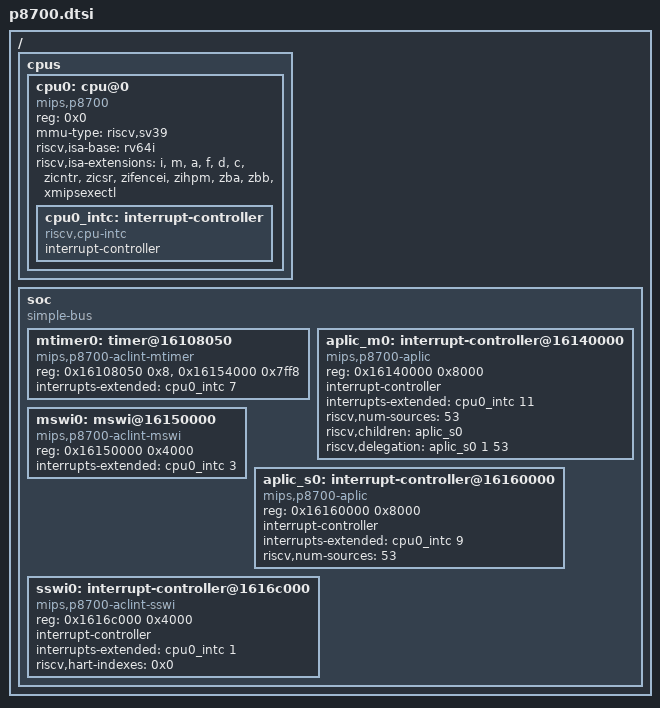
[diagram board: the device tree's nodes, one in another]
// SPDX-License-Identifier: (GPL-2.0-only OR BSD-2-Clause)
/*
 * Copyright (C) 2025 MIPS
 */

/ {
	#address-cells = <1>;
	#size-cells = <1>;

	cpus {
		#address-cells = <1>;
		#size-cells = <0>;

		cpu0: cpu@0 {
			device_type = "cpu";
			compatible = "mips,p8700", "riscv";
			reg = <0x0>;
			mmu-type = "riscv,sv39";
			riscv,isa-base = "rv64i";
			riscv,isa-extensions = "i", "m", "a", "f", "d", "c",
					       "zicntr", "zicsr", "zifencei",
					       "zihpm", "zba", "zbb",
					       "xmipsexectl";

			cpu0_intc: interrupt-controller {
				compatible = "riscv,cpu-intc";
				interrupt-controller;
				#interrupt-cells = <1>;
			};
		};
	};

	soc: soc {
		compatible = "simple-bus";
		#address-cells = <1>;
		#size-cells = <1>;
		ranges;

		mtimer0: timer@16108050 {
			compatible = "mips,p8700-aclint-mtimer";
			reg = <0x16108050 0x8>,
			      <0x16154000 0x7ff8>;
			reg-names = "mtime", "mtimecmp";
			interrupts-extended = <&cpu0_intc 7>;
		};

		aplic_m0: interrupt-controller@16140000 {
			compatible = "mips,p8700-aplic", "riscv,aplic";
			reg = <0x16140000 0x8000>;
			interrupt-controller;
			#interrupt-cells = <2>;
			interrupts-extended = <&cpu0_intc 11>;
			riscv,num-sources = <53>;
			riscv,children = <&aplic_s0>;
			riscv,delegation = <&aplic_s0 1 53>;
		};

		mswi0: mswi@16150000 {
			compatible = "mips,p8700-aclint-mswi";
			reg = <0x16150000 0x4000>;
			interrupts-extended = <&cpu0_intc 3>;
		};

		aplic_s0: interrupt-controller@16160000 {
			compatible = "mips,p8700-aplic", "riscv,aplic";
			reg = <0x16160000 0x8000>;
			interrupt-controller;
			#interrupt-cells = <2>;
			interrupts-extended = <&cpu0_intc 9>;
			riscv,num-sources = <53>;
		};

		sswi0: interrupt-controller@1616c000 {
			compatible = "mips,p8700-aclint-sswi";
			reg = <0x1616c000 0x4000>;
			interrupt-controller;
			#interrupt-cells = <0>;
			interrupts-extended = <&cpu0_intc 1>;
			riscv,hart-indexes = <0x0>;
		};
	};
};
